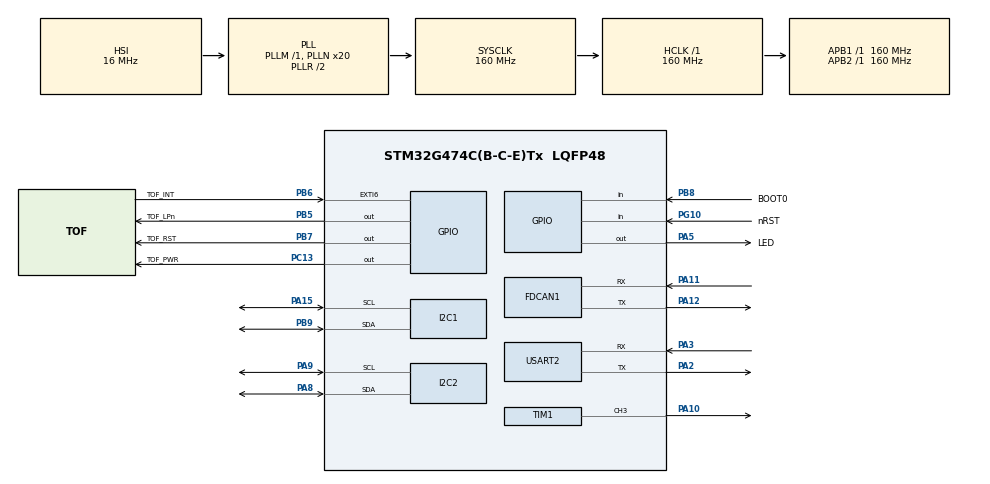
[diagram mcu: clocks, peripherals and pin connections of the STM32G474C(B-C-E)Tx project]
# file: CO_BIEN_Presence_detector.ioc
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Dma.Request0=TIM1_CH3
Dma.Request1=USART2_TX
Dma.TIM1_CH3.0.Direction=DMA_PERIPH_TO_MEMORY
Dma.TIM1_CH3.0.EventEnable=DISABLE
Dma.TIM1_CH3.0.Instance=DMA1_Channel1
Dma.TIM1_CH3.0.MemDataAlignment=DMA_MDATAALIGN_HALFWORD
Dma.TIM1_CH3.0.MemInc=DMA_MINC_ENABLE
Dma.TIM1_CH3.0.Mode=DMA_NORMAL
Dma.TIM1_CH3.0.PeriphDataAlignment=DMA_PDATAALIGN_HALFWORD
Dma.TIM1_CH3.0.PeriphInc=DMA_PINC_DISABLE
Dma.TIM1_CH3.0.Polarity=HAL_DMAMUX_REQ_GEN_RISING
Dma.TIM1_CH3.0.Priority=DMA_PRIORITY_LOW
Dma.TIM1_CH3.0.RequestNumber=1
Dma.TIM1_CH3.0.SignalID=NONE
Dma.TIM1_CH3.0.SyncEnable=DISABLE
Dma.TIM1_CH3.0.SyncPolarity=HAL_DMAMUX_SYNC_NO_EVENT
Dma.TIM1_CH3.0.SyncRequestNumber=1
Dma.TIM1_CH3.0.SyncSignalID=NONE
Dma.USART2_TX.1.Direction=DMA_MEMORY_TO_PERIPH
Dma.USART2_TX.1.EventEnable=DISABLE
Dma.USART2_TX.1.Instance=DMA1_Channel2
Dma.USART2_TX.1.MemDataAlignment=DMA_MDATAALIGN_BYTE
Dma.USART2_TX.1.MemInc=DMA_MINC_ENABLE
Dma.USART2_TX.1.Mode=DMA_NORMAL
Dma.USART2_TX.1.PeriphDataAlignment=DMA_PDATAALIGN_BYTE
Dma.USART2_TX.1.PeriphInc=DMA_PINC_DISABLE
Dma.USART2_TX.1.Polarity=HAL_DMAMUX_REQ_GEN_RISING
Dma.USART2_TX.1.Priority=DMA_PRIORITY_LOW
Dma.USART2_TX.1.RequestNumber=1
Dma.USART2_TX.1.SignalID=NONE
Dma.USART2_TX.1.SyncEnable=DISABLE
Dma.USART2_TX.1.SyncPolarity=HAL_DMAMUX_SYNC_NO_EVENT
Dma.USART2_TX.1.SyncRequestNumber=1
Dma.USART2_TX.1.SyncSignalID=NONE
FDCAN1.AutoRetransmission=ENABLE
FDCAN1.CalculateBaudRateNominal=500000
FDCAN1.CalculateTimeBitNominal=2000
FDCAN1.CalculateTimeQuantumNominal=500.0
FDCAN1.ClockDivider=FDCAN_CLOCK_DIV16
FDCAN1.NominalPrescaler=5
FDCAN1.NominalTimeSeg2=2
I2C1.Timing=0x30D29DE4
I2C2.Timing=0x30D29DE4
Mcu.Family=STM32G4
Mcu.Name=STM32G474C(B-C-E)Tx
Mcu.Package=LQFP48
NVIC.DMA1_Channel1_IRQn=true\:0\:0\:false\:false\:true\:false\:true\:true
NVIC.DMA1_Channel2_IRQn=true\:0\:0\:false\:false\:true\:false\:true\:true
NVIC.EXTI9_5_IRQn=true\:0\:0\:false\:false\:true\:true\:true\:true
NVIC.FDCAN1_IT0_IRQn=true\:0\:0\:false\:false\:true\:true\:true\:true
NVIC.FDCAN1_IT1_IRQn=true\:0\:0\:false\:false\:true\:true\:true\:true
NVIC.PriorityGroup=NVIC_PRIORITYGROUP_4
NVIC.USART2_IRQn=true\:0\:0\:false\:false\:true\:true\:true\:true
PA10.Signal=S_TIM1_CH3
PA11.Mode=FDCAN_Activate
PA11.Signal=FDCAN1_RX
PA12.Mode=FDCAN_Activate
PA12.Signal=FDCAN1_TX
PA13.Mode=Trace_Asynchronous_SW
PA13.Signal=SYS_JTMS-SWDIO
PA14.Mode=Trace_Asynchronous_SW
PA14.Signal=SYS_JTCK-SWCLK
PA15.Mode=I2C
PA15.Signal=I2C1_SCL
PA2.Mode=Asynchronous
PA2.Signal=USART2_TX
PA3.Mode=Asynchronous
PA3.Signal=USART2_RX
PA5.GPIO_Label=LED
PA5.Signal=GPIO_Output
PA8.Mode=I2C
PA8.Signal=I2C2_SDA
PA9.Mode=I2C
PA9.Signal=I2C2_SCL
PB3.Mode=Trace_Asynchronous_SW
PB3.Signal=SYS_JTDO-SWO
PB5.GPIO_Label=TOF_LPn
PB5.Signal=GPIO_Output
PB6.GPIO_Label=TOF_INT
PB6.Signal=GPXTI6
PB7.GPIO_Label=TOF_RST
PB7.Signal=GPIO_Output
PB8-BOOT0.GPIO_Label=BOOT0
PB8-BOOT0.Signal=GPIO_Input
PB9.Mode=I2C
PB9.Signal=I2C1_SDA
PC13.GPIO_Label=TOF_PWR
PC13.Signal=GPIO_Output
PG10-NRST.GPIO_Label=nRST
PG10-NRST.Signal=GPIO_Input
ProjectManager.HeapSize=0x200
ProjectManager.StackSize=0x400
ProjectManager.TargetToolchain=STM32CubeIDE
RCC.ADC12Freq_Value=160000000
RCC.ADC345Freq_Value=160000000
RCC.AHBFreq_Value=160000000
RCC.APB1Freq_Value=160000000
RCC.APB1TimFreq_Value=160000000
RCC.APB2Freq_Value=160000000
RCC.APB2TimFreq_Value=160000000
RCC.CortexFreq_Value=160000000
RCC.EXTERNAL_CLOCK_VALUE=12288000
RCC.HCLKFreq_Value=160000000
RCC.HSE_VALUE=8000000
RCC.HSI48_VALUE=48000000
RCC.HSI_VALUE=16000000
RCC.LSE_VALUE=32768
RCC.PLLN=20
RCC.SYSCLKFreq_VALUE=160000000
RCC.SYSCLKSource=RCC_SYSCLKSOURCE_PLLCLK
RCC.USBFreq_Value=160000000
RCC.VCOOutputFreq_Value=320000000
SH.S_TIM1_CH3.0=TIM1_CH3,PWM Generation3 CH3
TIM1.Channel-PWM\ Generation3\ CH3=TIM_CHANNEL_3
USART2.VirtualMode-Asynchronous=VM_ASYNC
VP_SYS_VS_DBSignals.Mode=DisableDeadBatterySignals
board=custom

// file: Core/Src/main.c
/* USER CODE BEGIN Header */
/**
 ******************************************************************************
 * @file           : main.c
 * @brief          : Main program body
 ******************************************************************************
 * @attention
 *
 * Copyright (c) 2025 STMicroelectronics.
 * All rights reserved.
 *
 * This software is licensed under terms that can be found in the LICENSE file
 * in the root directory of this software component.
 * If no LICENSE file comes with this software, it is provided AS-IS.
 *
 ******************************************************************************
 */
/* USER CODE END Header */
#include "main.h"

/* USER CODE BEGIN Includes */
#include <stdio.h>

#include "application.h"

/* USER CODE END Includes */

FDCAN_HandleTypeDef hfdcan1;

I2C_HandleTypeDef hi2c1;
I2C_HandleTypeDef hi2c2;

TIM_HandleTypeDef htim1;
DMA_HandleTypeDef hdma_tim1_ch3;

UART_HandleTypeDef huart2;
DMA_HandleTypeDef hdma_usart2_tx;

void SystemClock_Config(void);
static void MX_GPIO_Init(void);
static void MX_DMA_Init(void);
static void MX_FDCAN1_Init(void);
static void MX_I2C2_Init(void);
static void MX_USART2_UART_Init(void);
static void MX_TIM1_Init(void);
static void MX_I2C1_Init(void);

int main(void) {

    /* MCU Configuration--------------------------------------------------------*/

    /* Reset of all peripherals, Initializes the Flash interface and the Systick. */
    HAL_Init();

    /* Configure the system clock */
    SystemClock_Config();

    /* Initialize all configured peripherals */
    MX_GPIO_Init();
    MX_DMA_Init();
    MX_FDCAN1_Init();
    MX_I2C2_Init();
    MX_USART2_UART_Init();
    MX_TIM1_Init();
    MX_I2C1_Init();

    /* Infinite loop */
    /* USER CODE BEGIN WHILE */
    application_setup();

    while (1) {
        application_loop();
        /* USER CODE END WHILE */

    }
}

void SystemClock_Config(void) {
    RCC_OscInitTypeDef RCC_OscInitStruct = { 0 };
    RCC_ClkInitTypeDef RCC_ClkInitStruct = { 0 };

    /** Configure the main internal regulator output voltage
     */
    HAL_PWREx_ControlVoltageScaling(PWR_REGULATOR_VOLTAGE_SCALE1_BOOST);

    /** Initializes the RCC Oscillators according to the specified parameters
     * in the RCC_OscInitTypeDef structure.
     */
    RCC_OscInitStruct.OscillatorType = RCC_OSCILLATORTYPE_HSI;
    RCC_OscInitStruct.HSIState = RCC_HSI_ON;
    RCC_OscInitStruct.HSICalibrationValue = RCC_HSICALIBRATION_DEFAULT;
    RCC_OscInitStruct.PLL.PLLState = RCC_PLL_ON;
    RCC_OscInitStruct.PLL.PLLSource = RCC_PLLSOURCE_HSI;
    RCC_OscInitStruct.PLL.PLLM = RCC_PLLM_DIV1;
    RCC_OscInitStruct.PLL.PLLN = 20;
    RCC_OscInitStruct.PLL.PLLP = RCC_PLLP_DIV2;
    RCC_OscInitStruct.PLL.PLLQ = RCC_PLLQ_DIV2;
    RCC_OscInitStruct.PLL.PLLR = RCC_PLLR_DIV2;
    if (HAL_RCC_OscConfig(&RCC_OscInitStruct) != HAL_OK) {
        Error_Handler();
    }

    /** Initializes the CPU, AHB and APB buses clocks
     */
    RCC_ClkInitStruct.ClockType = RCC_CLOCKTYPE_HCLK | RCC_CLOCKTYPE_SYSCLK | RCC_CLOCKTYPE_PCLK1 | RCC_CLOCKTYPE_PCLK2;
    RCC_ClkInitStruct.SYSCLKSource = RCC_SYSCLKSOURCE_PLLCLK;
    RCC_ClkInitStruct.AHBCLKDivider = RCC_SYSCLK_DIV1;
    RCC_ClkInitStruct.APB1CLKDivider = RCC_HCLK_DIV1;
    RCC_ClkInitStruct.APB2CLKDivider = RCC_HCLK_DIV1;

    if (HAL_RCC_ClockConfig(&RCC_ClkInitStruct, FLASH_LATENCY_4) != HAL_OK) {
        Error_Handler();
    }
}

static void MX_FDCAN1_Init(void) {

    hfdcan1.Instance = FDCAN1;
    hfdcan1.Init.ClockDivider = FDCAN_CLOCK_DIV16;
    hfdcan1.Init.FrameFormat = FDCAN_FRAME_CLASSIC;
    hfdcan1.Init.Mode = FDCAN_MODE_NORMAL;
    hfdcan1.Init.AutoRetransmission = ENABLE;
    hfdcan1.Init.TransmitPause = DISABLE;
    hfdcan1.Init.ProtocolException = DISABLE;
    hfdcan1.Init.NominalPrescaler = 5;
    hfdcan1.Init.NominalSyncJumpWidth = 1;
    hfdcan1.Init.NominalTimeSeg1 = 1;
    hfdcan1.Init.NominalTimeSeg2 = 2;
    hfdcan1.Init.DataPrescaler = 1;
    hfdcan1.Init.DataSyncJumpWidth = 1;
    hfdcan1.Init.DataTimeSeg1 = 1;
    hfdcan1.Init.DataTimeSeg2 = 1;
    hfdcan1.Init.StdFiltersNbr = 0;
    hfdcan1.Init.ExtFiltersNbr = 0;
    hfdcan1.Init.TxFifoQueueMode = FDCAN_TX_FIFO_OPERATION;
    if (HAL_FDCAN_Init(&hfdcan1) != HAL_OK) {
        Error_Handler();
    }

}

static void MX_I2C1_Init(void) {

    hi2c1.Instance = I2C1;
    hi2c1.Init.Timing = 0x30D29DE4;
    hi2c1.Init.OwnAddress1 = 0;
    hi2c1.Init.AddressingMode = I2C_ADDRESSINGMODE_7BIT;
    hi2c1.Init.DualAddressMode = I2C_DUALADDRESS_DISABLE;
    hi2c1.Init.OwnAddress2 = 0;
    hi2c1.Init.OwnAddress2Masks = I2C_OA2_NOMASK;
    hi2c1.Init.GeneralCallMode = I2C_GENERALCALL_DISABLE;
    hi2c1.Init.NoStretchMode = I2C_NOSTRETCH_DISABLE;
    if (HAL_I2C_Init(&hi2c1) != HAL_OK) {
        Error_Handler();
    }

    /** Configure Analogue filter
     */
    if (HAL_I2CEx_ConfigAnalogFilter(&hi2c1, I2C_ANALOGFILTER_ENABLE) != HAL_OK) {
        Error_Handler();
    }

    /** Configure Digital filter
     */
    if (HAL_I2CEx_ConfigDigitalFilter(&hi2c1, 0) != HAL_OK) {
        Error_Handler();
    }

}

static void MX_I2C2_Init(void) {

    hi2c2.Instance = I2C2;
    hi2c2.Init.Timing = 0x30D29DE4;
    hi2c2.Init.OwnAddress1 = 0;
    hi2c2.Init.AddressingMode = I2C_ADDRESSINGMODE_7BIT;
    hi2c2.Init.DualAddressMode = I2C_DUALADDRESS_DISABLE;
    hi2c2.Init.OwnAddress2 = 0;
    hi2c2.Init.OwnAddress2Masks = I2C_OA2_NOMASK;
    hi2c2.Init.GeneralCallMode = I2C_GENERALCALL_DISABLE;
    hi2c2.Init.NoStretchMode = I2C_NOSTRETCH_DISABLE;
    if (HAL_I2C_Init(&hi2c2) != HAL_OK) {
        Error_Handler();
    }

    /** Configure Analogue filter
     */
    if (HAL_I2CEx_ConfigAnalogFilter(&hi2c2, I2C_ANALOGFILTER_ENABLE) != HAL_OK) {
        Error_Handler();
    }

    /** Configure Digital filter
     */
    if (HAL_I2CEx_ConfigDigitalFilter(&hi2c2, 0) != HAL_OK) {
        Error_Handler();
    }

}

static void MX_TIM1_Init(void) {

    TIM_MasterConfigTypeDef sMasterConfig = { 0 };
    TIM_OC_InitTypeDef sConfigOC = { 0 };
    TIM_BreakDeadTimeConfigTypeDef sBreakDeadTimeConfig = { 0 };

    htim1.Instance = TIM1;
    htim1.Init.Prescaler = 0;
    htim1.Init.CounterMode = TIM_COUNTERMODE_UP;
    htim1.Init.Period = 65535;
    htim1.Init.ClockDivision = TIM_CLOCKDIVISION_DIV1;
    htim1.Init.RepetitionCounter = 0;
    htim1.Init.AutoReloadPreload = TIM_AUTORELOAD_PRELOAD_DISABLE;
    if (HAL_TIM_PWM_Init(&htim1) != HAL_OK) {
        Error_Handler();
    }
    sMasterConfig.MasterOutputTrigger = TIM_TRGO_RESET;
    sMasterConfig.MasterOutputTrigger2 = TIM_TRGO2_RESET;
    sMasterConfig.MasterSlaveMode = TIM_MASTERSLAVEMODE_DISABLE;
    if (HAL_TIMEx_MasterConfigSynchronization(&htim1, &sMasterConfig) != HAL_OK) {
        Error_Handler();
    }
    sConfigOC.OCMode = TIM_OCMODE_PWM1;
    sConfigOC.Pulse = 0;
    sConfigOC.OCPolarity = TIM_OCPOLARITY_HIGH;
    sConfigOC.OCNPolarity = TIM_OCNPOLARITY_HIGH;
    sConfigOC.OCFastMode = TIM_OCFAST_DISABLE;
    sConfigOC.OCIdleState = TIM_OCIDLESTATE_RESET;
    sConfigOC.OCNIdleState = TIM_OCNIDLESTATE_RESET;
    if (HAL_TIM_PWM_ConfigChannel(&htim1, &sConfigOC, TIM_CHANNEL_3) != HAL_OK) {
        Error_Handler();
    }
    sBreakDeadTimeConfig.OffStateRunMode = TIM_OSSR_DISABLE;
    sBreakDeadTimeConfig.OffStateIDLEMode = TIM_OSSI_DISABLE;
    sBreakDeadTimeConfig.LockLevel = TIM_LOCKLEVEL_OFF;
    sBreakDeadTimeConfig.DeadTime = 0;
    sBreakDeadTimeConfig.BreakState = TIM_BREAK_DISABLE;
    sBreakDeadTimeConfig.BreakPolarity = TIM_BREAKPOLARITY_HIGH;
    sBreakDeadTimeConfig.BreakFilter = 0;
    sBreakDeadTimeConfig.BreakAFMode = TIM_BREAK_AFMODE_INPUT;
    sBreakDeadTimeConfig.Break2State = TIM_BREAK2_DISABLE;
    sBreakDeadTimeConfig.Break2Polarity = TIM_BREAK2POLARITY_HIGH;
    sBreakDeadTimeConfig.Break2Filter = 0;
    sBreakDeadTimeConfig.Break2AFMode = TIM_BREAK_AFMODE_INPUT;
    sBreakDeadTimeConfig.AutomaticOutput = TIM_AUTOMATICOUTPUT_DISABLE;
    if (HAL_TIMEx_ConfigBreakDeadTime(&htim1, &sBreakDeadTimeConfig) != HAL_OK) {
        Error_Handler();
    }
    HAL_TIM_MspPostInit(&htim1);

}

static void MX_USART2_UART_Init(void) {

    huart2.Instance = USART2;
    huart2.Init.BaudRate = 115200;
    huart2.Init.WordLength = UART_WORDLENGTH_8B;
    huart2.Init.StopBits = UART_STOPBITS_1;
    huart2.Init.Parity = UART_PARITY_NONE;
    huart2.Init.Mode = UART_MODE_TX_RX;
    huart2.Init.HwFlowCtl = UART_HWCONTROL_NONE;
    huart2.Init.OverSampling = UART_OVERSAMPLING_16;
    huart2.Init.OneBitSampling = UART_ONE_BIT_SAMPLE_DISABLE;
    huart2.Init.ClockPrescaler = UART_PRESCALER_DIV1;
    huart2.AdvancedInit.AdvFeatureInit = UART_ADVFEATURE_NO_INIT;
    if (HAL_UART_Init(&huart2) != HAL_OK) {
        Error_Handler();
    }
    if (HAL_UARTEx_SetTxFifoThreshold(&huart2, UART_TXFIFO_THRESHOLD_1_8) != HAL_OK) {
        Error_Handler();
    }
    if (HAL_UARTEx_SetRxFifoThreshold(&huart2, UART_RXFIFO_THRESHOLD_1_8) != HAL_OK) {
        Error_Handler();
    }
    if (HAL_UARTEx_DisableFifoMode(&huart2) != HAL_OK) {
        Error_Handler();
    }

}

static void MX_DMA_Init(void) {

    /* DMA controller clock enable */
    __HAL_RCC_DMAMUX1_CLK_ENABLE();
    __HAL_RCC_DMA1_CLK_ENABLE();

    /* DMA interrupt init */
    /* DMA1_Channel1_IRQn interrupt configuration */
    HAL_NVIC_SetPriority(DMA1_Channel1_IRQn, 0, 0);
    HAL_NVIC_EnableIRQ(DMA1_Channel1_IRQn);
    /* DMA1_Channel2_IRQn interrupt configuration */
    HAL_NVIC_SetPriority(DMA1_Channel2_IRQn, 0, 0);
    HAL_NVIC_EnableIRQ(DMA1_Channel2_IRQn);

}

static void MX_GPIO_Init(void) {
    GPIO_InitTypeDef GPIO_InitStruct = { 0 };

    /* GPIO Ports Clock Enable */
    __HAL_RCC_GPIOC_CLK_ENABLE();
    __HAL_RCC_GPIOG_CLK_ENABLE();
    __HAL_RCC_GPIOA_CLK_ENABLE();
    __HAL_RCC_GPIOB_CLK_ENABLE();

    /*Configure GPIO pin Output Level */
    HAL_GPIO_WritePin(TOF_PWR_GPIO_Port, TOF_PWR_Pin, GPIO_PIN_RESET);

    /*Configure GPIO pin Output Level */
    HAL_GPIO_WritePin(LED_GPIO_Port, LED_Pin, GPIO_PIN_RESET);

    /*Configure GPIO pin Output Level */
    HAL_GPIO_WritePin(GPIOB, TOF_LPn_Pin | TOF_RST_Pin, GPIO_PIN_RESET);

    /*Configure GPIO pin : TOF_PWR_Pin */
    GPIO_InitStruct.Pin = TOF_PWR_Pin;
    GPIO_InitStruct.Mode = GPIO_MODE_OUTPUT_PP;
    GPIO_InitStruct.Pull = GPIO_NOPULL;
    GPIO_InitStruct.Speed = GPIO_SPEED_FREQ_LOW;
    HAL_GPIO_Init(TOF_PWR_GPIO_Port, &GPIO_InitStruct);

    /*Configure GPIO pin : nRST_Pin */
    GPIO_InitStruct.Pin = nRST_Pin;
    GPIO_InitStruct.Mode = GPIO_MODE_INPUT;
    GPIO_InitStruct.Pull = GPIO_NOPULL;
    HAL_GPIO_Init(nRST_GPIO_Port, &GPIO_InitStruct);

    /*Configure GPIO pin : LED_Pin */
    GPIO_InitStruct.Pin = LED_Pin;
    GPIO_InitStruct.Mode = GPIO_MODE_OUTPUT_PP;
    GPIO_InitStruct.Pull = GPIO_NOPULL;
    GPIO_InitStruct.Speed = GPIO_SPEED_FREQ_LOW;
    HAL_GPIO_Init(LED_GPIO_Port, &GPIO_InitStruct);

    /*Configure GPIO pins : TOF_LPn_Pin TOF_RST_Pin */
    GPIO_InitStruct.Pin = TOF_LPn_Pin | TOF_RST_Pin;
    GPIO_InitStruct.Mode = GPIO_MODE_OUTPUT_PP;
    GPIO_InitStruct.Pull = GPIO_NOPULL;
    GPIO_InitStruct.Speed = GPIO_SPEED_FREQ_LOW;
    HAL_GPIO_Init(GPIOB, &GPIO_InitStruct);

    /*Configure GPIO pin : TOF_INT_Pin */
    GPIO_InitStruct.Pin = TOF_INT_Pin;
    GPIO_InitStruct.Mode = GPIO_MODE_IT_RISING;
    GPIO_InitStruct.Pull = GPIO_NOPULL;
    HAL_GPIO_Init(TOF_INT_GPIO_Port, &GPIO_InitStruct);

    /*Configure GPIO pin : BOOT0_Pin */
    GPIO_InitStruct.Pin = BOOT0_Pin;
    GPIO_InitStruct.Mode = GPIO_MODE_INPUT;
    GPIO_InitStruct.Pull = GPIO_NOPULL;
    HAL_GPIO_Init(BOOT0_GPIO_Port, &GPIO_InitStruct);

    /* EXTI interrupt init*/
    HAL_NVIC_SetPriority(EXTI9_5_IRQn, 0, 0);
    HAL_NVIC_EnableIRQ(EXTI9_5_IRQn);

}

void Error_Handler(void) {
    /* USER CODE BEGIN Error_Handler_Debug */
    /* User can add his own implementation to report the HAL error return state */
    __disable_irq();
    while (1) {
        for (int n = 0; n < 1000; n++) {
            HAL_GPIO_TogglePin(LED_GPIO_Port, LED_Pin);
            for (uint64_t i = 0; i < 150000; i++) {
                __asm__("nop");
            }
        }
        // HAL_Delay (50); //plus d'it, donc plus de tick
        NVIC_SystemReset();
        /* USER CODE END Error_Handler_Debug */
    }
}
